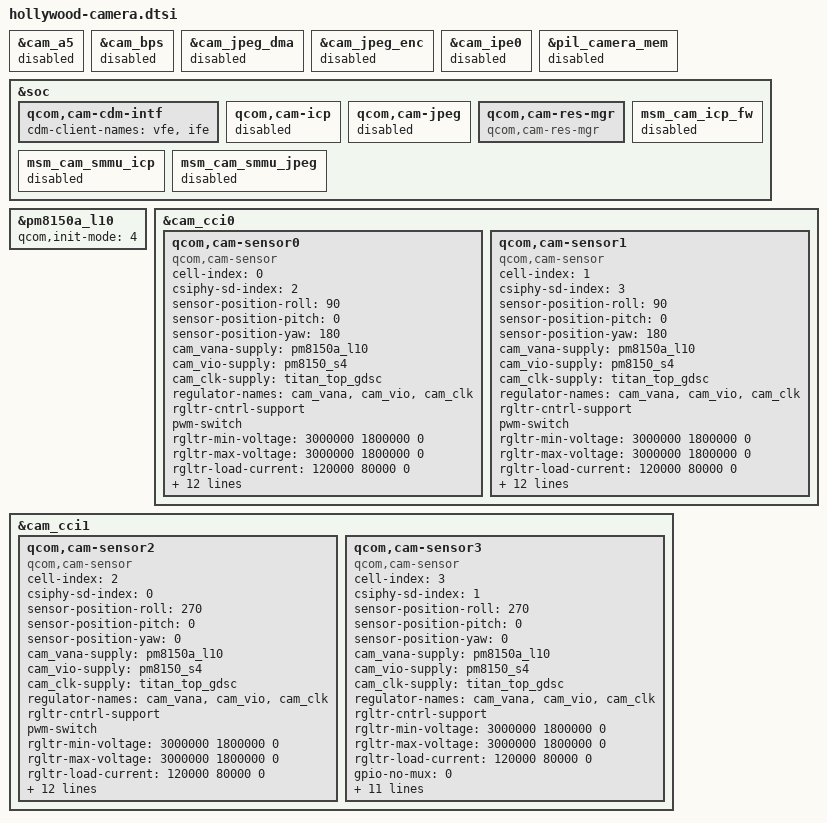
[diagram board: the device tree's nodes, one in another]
&cam_a5 {
	status = "disabled";
};

&cam_bps {
	status = "disabled";
};

&cam_jpeg_dma {
	status = "disabled";
};

&cam_jpeg_enc {
	status = "disabled";
};

&cam_ipe0 {
	status = "disabled";
};

&pil_camera_mem {
	status = "disabled";
};

&soc {
	qcom,cam-cdm-intf {
		cdm-client-names = "vfe", "ife";
	};

	qcom,cam-icp {
		status = "disabled";
	};

	qcom,cam-jpeg {
		status = "disabled";
	};

	qcom,cam-res-mgr {
		compatible = "qcom,cam-res-mgr";
		status = "ok";
	};

	msm_cam_icp_fw {
		status = "disabled";
	};

	msm_cam_smmu_icp {
		status = "disabled";
	};

	msm_cam_smmu_jpeg {
		status = "disabled";
	};
};

&pm8150a_l10 {
	qcom,init-mode = <4>; /* RPMH_REGULATOR_MODE_HPM */
};

&cam_cci0 {
	qcom,cam-sensor0 {
		cell-index = <0>;
		compatible = "qcom,cam-sensor";
		csiphy-sd-index = <2>;
		sensor-position-roll = <90>;
		sensor-position-pitch = <0>;
		sensor-position-yaw = <180>;
		cam_vana-supply = <&pm8150a_l10>;
		cam_vio-supply = <&pm8150_s4>;
		cam_clk-supply = <&titan_top_gdsc>;
		regulator-names = "cam_vana", "cam_vio", "cam_clk";
		rgltr-cntrl-support;
		pwm-switch;
		rgltr-min-voltage = <3000000 1800000 0>;
		rgltr-max-voltage = <3000000 1800000 0>;
		rgltr-load-current = <120000 80000 0>;
		gpio-no-mux = <0>;
		pinctrl-names = "cam_default", "cam_suspend";
		pinctrl-0 = <&cam_sensor_mclk2_active>;
		pinctrl-1 = <&cam_sensor_mclk2_suspend>;
		gpios = <&tlmm 96 0>;
		gpio-req-tbl-num = <0>;
		gpio-req-tbl-flags = <1>;
		gpio-req-tbl-label = "CAMIF_MCLK2";
		sensor-mode = <0>;
		cci-master = <0>;
		status = "ok";
		clocks = <&clock_camcc CAM_CC_MCLK2_CLK>;
		clock-names = "cam_clk";
		clock-cntl-level = "turbo";
		clock-rates = <24000000>;
	};

	qcom,cam-sensor1 {
		cell-index = <1>;
		compatible = "qcom,cam-sensor";
		csiphy-sd-index = <3>;
		sensor-position-roll = <90>;
		sensor-position-pitch = <0>;
		sensor-position-yaw = <180>;
		cam_vana-supply = <&pm8150a_l10>;
		cam_vio-supply = <&pm8150_s4>;
		cam_clk-supply = <&titan_top_gdsc>;
		regulator-names = "cam_vana", "cam_vio", "cam_clk";
		rgltr-cntrl-support;
		pwm-switch;
		rgltr-min-voltage = <3000000 1800000 0>;
		rgltr-max-voltage = <3000000 1800000 0>;
		rgltr-load-current = <120000 80000 0>;
		gpio-no-mux = <0>;
		pinctrl-names = "cam_default", "cam_suspend";
		pinctrl-0 = <&cam_sensor_mclk3_active>;
		pinctrl-1 = <&cam_sensor_mclk3_suspend>;
		gpios = <&tlmm 97 0>;
		gpio-req-tbl-num = <0>;
		gpio-req-tbl-flags = <1>;
		gpio-req-tbl-label = "CAMIF_MCLK3";
		sensor-mode = <0>;
		cci-master = <1>;
		status = "ok";
		clocks = <&clock_camcc CAM_CC_MCLK3_CLK>;
		clock-names = "cam_clk";
		clock-cntl-level = "turbo";
		clock-rates = <24000000>;
	};
};

&cam_cci1 {
	qcom,cam-sensor2 {
		cell-index = <2>;
		compatible = "qcom,cam-sensor";
		csiphy-sd-index = <0>;
		sensor-position-roll = <270>;
		sensor-position-pitch = <0>;
		sensor-position-yaw = <0>;
		cam_vana-supply = <&pm8150a_l10>;
		cam_vio-supply = <&pm8150_s4>;
		cam_clk-supply = <&titan_top_gdsc>;
		regulator-names = "cam_vana", "cam_vio", "cam_clk";
		rgltr-cntrl-support;
		pwm-switch;
		rgltr-min-voltage = <3000000 1800000 0>;
		rgltr-max-voltage = <3000000 1800000 0>;
		rgltr-load-current = <120000 80000 0>;
		gpio-no-mux = <0>;
		pinctrl-names = "cam_default", "cam_suspend";
		pinctrl-0 = <&cam_sensor_mclk0_active>;
		pinctrl-1 = <&cam_sensor_mclk0_suspend>;
		gpios = <&tlmm 94 0>;
		gpio-req-tbl-num = <0>;
		gpio-req-tbl-flags = <1>;
		gpio-req-tbl-label = "CAMIF_MCLK0";
		sensor-mode = <0>;
		cci-master = <0>;
		status = "ok";
		clocks = <&clock_camcc CAM_CC_MCLK0_CLK>;
		clock-names = "cam_clk";
		clock-cntl-level = "turbo";
		clock-rates = <24000000>;
	};

	qcom,cam-sensor3 {
		cell-index = <3>;
		compatible = "qcom,cam-sensor";
		csiphy-sd-index = <1>;
		sensor-position-roll = <270>;
		sensor-position-pitch = <0>;
		sensor-position-yaw = <0>;
		cam_vana-supply = <&pm8150a_l10>;
		cam_vio-supply = <&pm8150_s4>;
		cam_clk-supply = <&titan_top_gdsc>;
		regulator-names = "cam_vana", "cam_vio", "cam_clk";
		rgltr-cntrl-support;
		rgltr-min-voltage = <3000000 1800000 0>;
		rgltr-max-voltage = <3000000 1800000 0>;
		rgltr-load-current = <120000 80000 0>;
		gpio-no-mux = <0>;
		pinctrl-names = "cam_default", "cam_suspend";
		pinctrl-0 = <&cam_sensor_mclk1_active>;
		pinctrl-1 = <&cam_sensor_mclk1_suspend>;
		gpios = <&tlmm 95 0>;
		gpio-req-tbl-num = <0>;
		gpio-req-tbl-flags = <1>;
		gpio-req-tbl-label = "CAMIF_MCLK1";
		sensor-mode = <0>;
		cci-master = <1>;
		status = "ok";
		clocks = <&clock_camcc CAM_CC_MCLK1_CLK>;
		clock-names = "cam_clk";
		clock-cntl-level = "turbo";
		clock-rates = <24000000>;
	};
};
